# LPC55S66_cm33_core1 register map
Vendor: nxp.com; File version: 1.0
CPU: CM33 r2p0, little endian, no MPU, no FPU, VTOR, 3 interrupt priority bits
Registers are 32-bit, read-write, reset 0x0 unless marked. A register's access mark holds for its fields unless they carry their own. Offsets are from the block's base; [hi:lo] are bit positions; lines under a group give offsets from that group; {n}, {i} and the like mark numbered series.

## MAILBOX
Base 0x4008B000
{0x0+0x10*i} MBOXIRQ[{i}] (i=0..1) group
  0x00 IRQ — Interrupt request register for the Cortex-M0+ CPU.
    [31:0] INTREQ — If any bit is set, an interrupt request is sent to the Cortex-M0+ interrupt controller.
  0x04 IRQSET wo reset not defined — Set bits in IRQ0
    [31:0] INTREQSET — Writing 1 sets the corresponding bit in the IRQ0 register.
  0x08 IRQCLR wo reset not defined — Clear bits in IRQ0
    [31:0] INTREQCLR — Writing 1 clears the corresponding bit in the IRQ0 register.
0xF8 MUTEX reset 0x1 — Mutual exclusion register[1]
  [0] EX — Cleared when read, set when written. See usage description above.

## CRC_ENGINE
Base 0x40095000
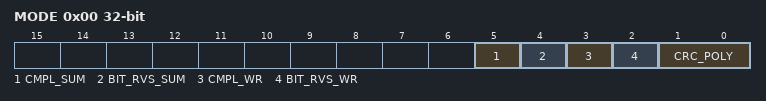
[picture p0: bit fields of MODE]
0x00 MODE — CRC mode register
  [5] CMPL_SUM — CRC sum complement: 1 = 1's complement for CRC_SUM 0 = No 1's complement for CRC_SUM
  [4] BIT_RVS_SUM — CRC sum bit order: 1 = Bit order reverse for CRC_SUM 0 = No bit order reverse for CRC_SUM
  [3] CMPL_WR — Data complement: 1 = 1's complement for CRC_WR_DATA 0 = No 1's complement for CRC_WR_DATA
  [2] BIT_RVS_WR — Data bit order: 1 = Bit order reverse for CRC_WR_DATA (per byte) 0 = No bit order reverse for CRC_WR_DATA (per byte)
  [1:0] CRC_POLY — CRC polynomial: 1X = CRC-32 polynomial 01 = CRC-16 polynomial 00 = CRC-CCITT polynomial
0x04 SEED reset 0xFFFF — CRC seed register
  [31:0] CRC_SEED — A write access to this register will load CRC seed value to CRC_SUM register with selected bit order and 1's complement pre-processes. A write access to this register will overrule the CRC calculation in progresses.
0x08 SUM ro reset 0xFFFF (SUM_WR_DATA view) — CRC checksum register
  [31:0] CRC_SUM — The most recent CRC sum can be read through this register with selected bit order and 1's complement post-processes.
0x08 WR_DATA wo reset not defined (SUM_WR_DATA view) — CRC data register
  [31:0] CRC_WR_DATA — Data written to this register will be taken to perform CRC calculation with selected bit order and 1's complement pre-process. Any write size 8, 16 or 32-bit are allowed and accept back-to-back transactions.

## DBGMAILBOX — MCU Debugger Mailbox
Base 0x4009C000
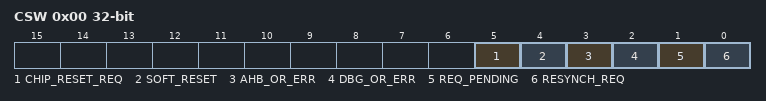
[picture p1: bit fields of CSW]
0x00 CSW — CRC mode register
  [5] CHIP_RESET_REQ wo — Write only bit. Once written will cause the chip to reset (note that the DM is not reset by this reset as it is only resettable by a SOFT reset or a POR/BOD event)
  [4] SOFT_RESET — Soft Reset for DM (write-only from AHB, not readable and selfclearing). A write to this bit will cause a soft reset for DM.
  [3] AHB_OR_ERR — AHB overrun Error (Return value overwritten by ROM)
  [2] DBG_OR_ERR — Debugger overrun error (previous REQUEST overwritten before being picked up by ROM)
  [1] REQ_PENDING — Request is pending from debugger (i.e unread value in REQUEST)
  [0] RESYNCH_REQ — Debugger will set this bit to 1 to request a resynchronrisation
0x04 REQUEST reset 0xFFFF — CRC seed register
  [31:0] REQ — Request Value
0x08 RETURN — Return value from ROM.
  [31:0] RET — The Return value from ROM.
0xFC ID ro reset 0x2A0000 — Identification register
  [31:0] ID — Identification value.

## SCnSCB
Base 0xE000E000
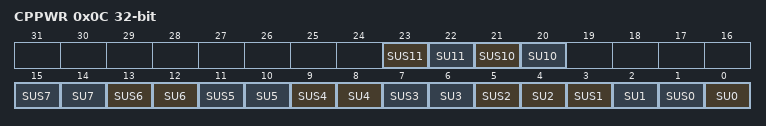
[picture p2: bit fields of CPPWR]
0x0C CPPWR reset not defined — Coprocessor Power Control Register
  [23] SUS11 — State UNKNOWN Secure only 11.
  [22] SU11 — State UNKNOWN 11.
  [21] SUS10 — State UNKNOWN Secure only 10.
    0=SECURE_AND_NON_SECURE (The SU10 field is accessible from both Security states.); 1=SECURE_ONLY (The SU10 field is only accessible from the Secure state.)
  [20] SU10 — State UNKNOWN 10.
    0=UNKNOWN_NOT_PERMITTED (The floating-point state is not permitted to become UNKNOWN.); 1=UNKNOWN_PERMITTED (The floating-point state is permitted to become UNKNOWN)
  [2n+1] SUS{n} (n=2..7) — State UNKNOWN Secure only {n}.
    0=SECURE_AND_NON_SECURE (The SU{n} field is accessible from both Security states.); 1=SECURE_ONLY (The SU{n} field is only accessible from the Secure state.)
  [2n] SU{n} (n=0..7) — State UNKNOWN {n}.
    0=UNKNOWN_NOT_PERMITTED (The coprocessor state is not permitted to become UNKNOWN.); 1=UNKNOWN_PERMITTED (The coprocessor state is permitted to become UNKNOWN.)
  [3] SUS1 — State UNKNOWN Secure only 1.
    0=SECURE_AND_NON_SECURE (The SU7 field is accessible from both Security states.); 1=SECURE_ONLY (The SU7 field is only accessible from the Secure state.)
  [1] SUS0 — State UNKNOWN Secure only 0.
    0=SECURE_AND_NON_SECURE (The SU0 field is accessible from both Security states.); 1=SECURE_ONLY (The SU0 field is only accessible from the Secure state.)
